# nrf54ls05b_enga_application register map
Vendor: Nordic Semiconductor; Series: nrf54l; File version: 1
CPU: CM33 r0p4, little endian, no MPU, no FPU, 3 interrupt priority bits, 270 interrupts
Registers are 32-bit, read-write, reset 0x0 unless marked. A register's access mark holds for its fields unless they carry their own. Offsets are from the block's base; [hi:lo] are bit positions; lines under a group give offsets from that group; {n}, {i} and the like mark numbered series.

## GLOBAL_SPU00 — System protection unit 0
Base 0x40040000
Same registers: GLOBAL_SPU10 0x40080000, GLOBAL_SPU20 0x400C0000, GLOBAL_SPU30 0x40100000
0x100 EVENTS_PERIPHACCERR — A security violation has been detected on one or several peripherals
  [0] EVENTS_PERIPHACCERR
    0=NotGenerated (Event not generated); 1=Generated (Event generated)
0x300 INTEN — Enable or disable interrupt
  [0] PERIPHACCERR — Enable or disable interrupt for event PERIPHACCERR
    0=Disabled; 1=Enabled
0x304 INTENSET — Enable interrupt
  [0] PERIPHACCERR — Write '1' to enable interrupt for event PERIPHACCERR
    on read: 0=Disabled (Read: Disabled); 1=Enabled (Read: Enabled) | on write: 1=Set (Enable)
0x308 INTENCLR — Disable interrupt
  [0] PERIPHACCERR — Write '1' to disable interrupt for event PERIPHACCERR
    on read: 0=Disabled (Read: Disabled); 1=Enabled (Read: Enabled) | on write: 1=Clear (Disable)
0x30C INTPEND ro — Pending interrupts
  [0] PERIPHACCERR — Read pending status of interrupt for event PERIPHACCERR
    on read: 0=NotPending (Read: Not pending); 1=Pending (Read: Pending)
0x404 PERIPHACCERR group — Unspecified
  0x00 ADDRESS ro — Address of the transaction that caused first error.
    [15:0] ADDRESS
{0x500+4i} PERIPH[{i}] (i=0..63) group — Unspecified
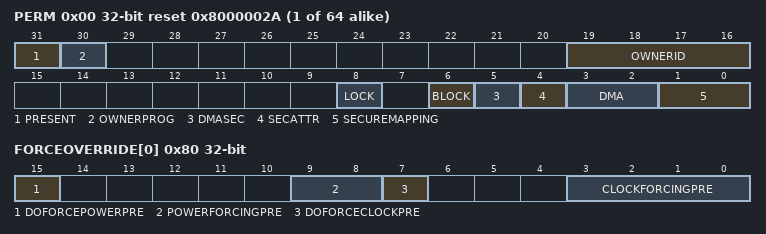
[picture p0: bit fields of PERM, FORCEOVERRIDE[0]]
  0x00 PERM reset 0x8000002A — Description cluster: Get and set the applicable access permissions for the peripheral slave index n
    [31] PRESENT ro — Indicates if a peripheral is present with peripheral slave index n
      0=NotPresent (Peripheral is not present); 1=IsPresent (Peripheral is present)
    [30] OWNERPROG ro — Indicates if OWNERID is programmable or not
      0=NotProgrammable (OWNERID is not programmable); 1=Programmable (OWNERID is programmable)
    [19:16] OWNERID — Peripheral owner ID
    [8] LOCK write-1-sets
      0=Unlocked (This register can be updated); 1=Locked (The content of this register can not be changed until the next reset)
    [6] BLOCK write-1-sets — Peripheral block
      0=Available (Peripheral is accessible); 1=Blocked (Peripheral cannot be accessed until next reset)
    [5] DMASEC — Security attribution for the DMA transfer
      1=Secure (DMA transfers initiated by this peripheral have the secure attribute set); 0=NonSecure (DMA transfers initiated by this peripheral have the non-secure attribute set)
    [4] SECATTR — Peripheral security mapping
      1=Secure (Peripheral is mapped in secure peripheral address space); 0=NonSecure (If SECUREMAPPING == UserSelectable: Peripheral is mapped in non-secure peripheral address space. If SECUREMAPPING == Split: Peripheral is mapped in non-secure and secure peripheral address space.)
    [3:2] DMA ro — Read the peripheral DMA capabilities
      0=NoDMA (Peripheral has no DMA capability); 1=NoSeparateAttribute (Peripheral has DMA and DMA transfers always have the same security attribute as assigned to the peripheral); 2=SeparateAttribute (Peripheral has DMA and DMA transfers can have a different security attribute than the one assigned to the peripheral)
    [1:0] SECUREMAPPING ro — Read capabilities for TrustZone Cortex-M secure attribute
      0=NonSecure (This peripheral is always accessible as a non-secure peripheral); 1=Secure (This peripheral is always accessible as a secure peripheral); 2=UserSelectable (Non-secure or secure attribute for this peripheral is defined by the PERIPH[n].PERM register); 3=Split (This peripheral implements the split security mechanism.)
0xF00 PCGCS group — Unspecified
  {0x0+4j} PENALTY[{j}] (j=0..0) reset 0xFFFFFFFC — Description collection: Penalty level for power/clock pair n. When FULL_PCP_ZERO feature is not supported, PENALTY[0] address overlaps the PENALTY0 address and register description for PENALTY[0] is not valid.
    [1:0] PENALTY — Penalty level
  {0x80+4j} FORCEOVERRIDE[{j}] (j=0..0) — Description collection: Force override of power/clock pair n.
    [15] DOFORCEPOWERPRE, [9:8] POWERFORCINGPRE, [7] DOFORCECLOCKPRE, [3:0] CLOCKFORCINGPRE
